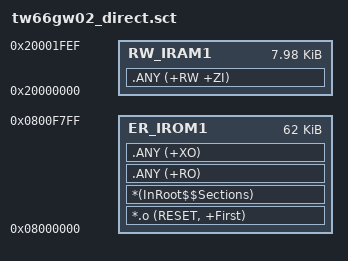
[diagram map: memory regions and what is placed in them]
LR_IROM1 0x08000000 0x0000F800 {
  ER_IROM1 0x08000000 0x0000F800 {
    *.o (RESET, +First)
    *(InRoot$$Sections)
    .ANY (+RO)
    .ANY (+XO)
  }
  RW_IRAM1 0x20000000 0x00001FF0 {
    .ANY (+RW +ZI)
  }
}
